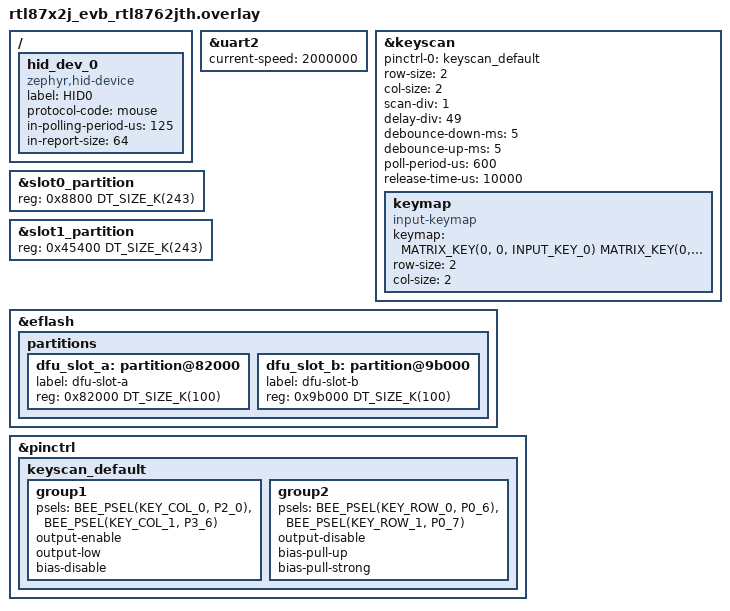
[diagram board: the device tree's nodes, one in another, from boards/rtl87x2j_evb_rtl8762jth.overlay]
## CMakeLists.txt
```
# Copyright (c) 2026 Realtek Semiconductor Corp.
# SPDX-License-Identifier: Apache-2.0

cmake_minimum_required(VERSION 3.20.0)
find_package(Zephyr REQUIRED HINTS $ENV{ZEPHYR_BASE})
project(hid_mouse)

include(${ZEPHYR_BASE}/samples/subsys/usb/common/common.cmake)

target_sources(app PRIVATE src/main.c src/dfu_slots.c)
```

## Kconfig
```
# Copyright (c) 2026, Realtek Semiconductor Corporation
# SPDX-License-Identifier: Apache-2.0

# Pull in the common USB sample options (SAMPLE_USBD_* etc.) - this also
# provides CONFIG_SAMPLE_USBD_REMOTE_WAKEUP which arms the device.
source "samples/subsys/usb/common/Kconfig.sample_usbd"

config APP_DFU_MODE_PID
	hex "Product ID of the DFU mode device"
	default 0xffff
	help
	  Product ID used by the DFU mode device, which replaces the run-time
	  HID device after DFU_DETACH. It must differ from CONFIG_SAMPLE_USBD_PID
	  so the host does not reuse the cached HID configuration.

source "Kconfig.zephyr"
```

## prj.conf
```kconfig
# Copyright (c) 2026 Realtek Semiconductor Corp.
# SPDX-License-Identifier: Apache-2.0

CONFIG_LOG=y
CONFIG_USB_DEVICE_STACK_NEXT=y
CONFIG_USBD_HID_SUPPORT=y
# Remote wakeup: the config descriptor carries the remote-wakeup attribute so
# the host knows the device can wake the bus. The host still must explicitly
# arm it (SET_FEATURE(DEVICE_REMOTE_WAKEUP)) before usbd_wakeup_request()
# succeeds, otherwise it returns -EACCES.
CONFIG_SAMPLE_USBD_REMOTE_WAKEUP=y
CONFIG_INPUT=y
# "stream on|off" switches the continuous reporting.
CONFIG_SHELL=y

# DFU: the run-time instance is registered next to the HID interface, the DFU
# mode instance ("dfu_dfu") is blocklisted by the common sample code and only
# registered by switch_to_dfu_mode(). The built-in flash backend is left off,
# src/dfu_slots.c drives the two partitions through flash_area_* instead.
CONFIG_USBD_DFU=y
CONFIG_USBD_DFU_NUMOF_IMAGES=2
CONFIG_FLASH=y
CONFIG_FLASH_MAP=y
CONFIG_FLASH_PAGE_LAYOUT=y

# switch_to_dfu_mode() runs on the system workqueue (cooperative priority) and
# tears USB down there, which starves the deferred log thread.
CONFIG_LOG_MODE_IMMEDIATE=y

# In immediate mode the whole formatting chain runs inline on the calling
# thread, and z_log_msg_runtime_vcreate() alloca()s the packaged message there,
# so a single log call needs ~1K of stack. The DWC2 driver thread logs from its
# per-transfer path (dwc2_prep_rx(), dwc2_set_dedicated_fifo()), which is more
# than the 512 byte default stack can absorb. Drop those to WRN (as the other
# USB samples do) and give the driver thread room for the WRN/ERR calls that
# remain.
CONFIG_UDC_DRIVER_LOG_LEVEL_WRN=y
CONFIG_USBD_LOG_LEVEL_WRN=y
CONFIG_UDC_DWC2_STACK_SIZE=1024

# Continuous reporting keeps 4 reports in flight, plus the one being released
# when the next is queued and an event report.
CONFIG_USBD_HID_IN_BUF_COUNT=6
```

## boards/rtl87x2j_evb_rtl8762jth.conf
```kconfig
# Copyright (c) 2026 Realtek Semiconductor Corp.
# SPDX-License-Identifier: Apache-2.0

CONFIG_BEE_INPUT_KEYSCAN_AUTOSCAN_MODE=y
# In auto scan mode the keyscan driver reports its events from the ISR with
# K_FOREVER. Through the input thread a full queue then pends whatever thread
# the ISR interrupted, and the input thread runs at the lowest priority, so at
# the 8 kHz report rate it falls behind and the queue does fill up. Run the
# callbacks right in the reporting context instead, they only update a few
# variables.
CONFIG_INPUT_MODE_SYNCHRONOUS=y
```

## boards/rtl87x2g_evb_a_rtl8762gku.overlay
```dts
/*
 * Copyright (c) 2026, Realtek Semiconductor Corporation
 *
 * SPDX-License-Identifier: Apache-2.0
 */

/ {
	hid_dev_0: hid_dev_0 {
		compatible = "zephyr,hid-device";
		label = "HID0";
		/* "mouse" makes the device advertise the HID boot interface
		 * (bInterfaceSubClass=1, bInterfaceProtocol=2), so the host may
		 * switch it to Boot Protocol via SET_PROTOCOL (e.g. BIOS/UEFI).
		 */
		protocol-code = "mouse";
		in-polling-period-us = <1000>;
		in-report-size = <64>;
	};
};

/* The board layout has no slot-0/slot-1 partitions, so the two DFU slots are
 * carved out of the free space that app-image otherwise claims. The 828K
 * between 0x2d000 and 0xfc000 (where storage starts) is split into 316K for
 * the application plus two 256K slots. Both offsets are 4K aligned, matching
 * the flash erase-block size.
 */
&app_partition {
	reg = <0x2d000 DT_SIZE_K(316)>;
};

&flash {
	partitions {
		dfu_slot_a: partition@7c000 {
			label = "dfu-slot-a";
			reg = <0x7c000 DT_SIZE_K(256)>;
		};

		dfu_slot_b: partition@bc000 {
			label = "dfu-slot-b";
			reg = <0xbc000 DT_SIZE_K(256)>;
		};
	};
};
```

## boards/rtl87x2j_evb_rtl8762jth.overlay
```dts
/*
 * Copyright (c) 2026, Realtek Semiconductor Corporation
 *
 * SPDX-License-Identifier: Apache-2.0
 */

#include <zephyr/dt-bindings/input/keymap.h>

/ {
	hid_dev_0: hid_dev_0 {
		compatible = "zephyr,hid-device";
		label = "HID0";
		/* "mouse" makes the device advertise the HID boot interface
		 * (bInterfaceSubClass=1, bInterfaceProtocol=2), so the host may
		 * switch it to Boot Protocol via SET_PROTOCOL (e.g. BIOS/UEFI).
		 */
		protocol-code = "mouse";
		in-polling-period-us = <125>;
		in-report-size = <64>;
	};
};

/* Faster console, so logging keeps up with the 8 kHz report rate. */
&uart2 {
	current-speed = <2000000>;
};

/* Mouse mode: keys are scanned every 1 ms, which is plenty for buttons next to
 * the 8 kHz sensor data. Timing rules:
 *  - The delay clock is 5 MHz / 2 / 50 = 50 kHz (20 us per tick), every timer
 *    counts at most 511 ticks.
 *  - The software debounce only remembers the last 30 scans (30 ms here).
 *  - As a precaution the release time is kept longer than the release
 *    debounce, so the all-release interrupt cannot come before the release
 *    has been debounced.
 */
&keyscan {
	pinctrl-0 = <&keyscan_default>;
	pinctrl-names = "default";
	row-size = <2>;
	col-size = <2>;
	scan-div = <1>;
	delay-div = <49>;
	debounce-down-ms = <5>;
	debounce-up-ms = <5>;
	poll-period-us = <600>;
	release-time-us = <10000>;
	status = "okay";

	/* Turns the row/column events of the matrix into the key codes the
	 * sample handles: left button, right button, move X, move Y.
	 */
	keymap {
		compatible = "input-keymap";
		keymap = <MATRIX_KEY(0, 0, INPUT_KEY_0)
			  MATRIX_KEY(0, 1, INPUT_KEY_1)
			  MATRIX_KEY(1, 0, INPUT_KEY_2)
			  MATRIX_KEY(1, 1, INPUT_KEY_3)>;
		row-size = <2>;
		col-size = <2>;
	};
};

/* The MCUboot layout (boot-patch + two 343K image slots) fills the whole
 * eflash, so both image slots are shrunk to 243K and the two DFU slots take
 * the 200K freed at the end. Both offsets are 1K aligned, matching the eflash
 * erase-block size. MCUboot must see the same layout, see
 * sysbuild/mcuboot.overlay.
 */
&slot0_partition {
	reg = <0x8800 DT_SIZE_K(243)>;
};

&slot1_partition {
	reg = <0x45400 DT_SIZE_K(243)>;
};

&eflash {
	partitions {
		dfu_slot_a: partition@82000 {
			label = "dfu-slot-a";
			reg = <0x82000 DT_SIZE_K(100)>;
		};

		dfu_slot_b: partition@9b000 {
			label = "dfu-slot-b";
			reg = <0x9b000 DT_SIZE_K(100)>;
		};
	};
};

&pinctrl {
	keyscan_default: keyscan_default {
		group1 {
			psels = <BEE_PSEL(KEY_COL_0, P2_0)>,
				<BEE_PSEL(KEY_COL_1, P3_6)>;
			output-enable;
			output-low;
			bias-disable;
		};

		group2 {
			psels = <BEE_PSEL(KEY_ROW_0, P0_6)>,
				<BEE_PSEL(KEY_ROW_1, P0_7)>;
			output-disable;
			bias-pull-up;
			bias-pull-strong;
		};
	};
};
```

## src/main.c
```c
/*
 * Copyright (c) 2026, Realtek Semiconductor Corporation
 *
 * SPDX-License-Identifier: Apache-2.0
 */

/* USB HID mouse demo combining boot-report support and remote wakeup.
 *
 * The device presents a HID mouse that supports the HID *boot interface*
 * (bInterfaceSubClass=1, bInterfaceProtocol=2) *and* is armed for remote
 * wakeup (remote-wakeup attribute in the configuration descriptor).
 *
 * Boot/report protocol switch:
 *   - Report Protocol (HID_PROTOCOL_REPORT, value 1): the 4-byte layout from
 *     the report descriptor.
 *   - Boot Protocol   (HID_PROTOCOL_BOOT, value 0):  the fixed 3-byte boot
 *     mouse report (buttons | X | Y) used by BIOS/UEFI. The host selects the
 *     protocol via SET_PROTOCOL; get_report() answers a host GET_REPORT with
 *     the matching layout.
 *
 * Remote wakeup:
 *   When the host suspends the bus, mouse activity triggers
 *   usbd_wakeup_request(), which drives a bus resume (K state). The suspend
 *   state is polled periodically (PROBE) so a lost USBSUSP interrupt can be
 *   told apart from a host that never suspended the bus.
 *
 * Continuous reporting:
 *   While the mouse is in normal use (configured, Report Protocol, bus not
 *   suspended) a report is sent on every host poll, 8 kHz on rtl87x2j. Under
 *   the Boot Protocol and while the bus is suspended each input event is
 *   handled on its own instead, as a boot report or a remote wakeup request.
 *   The shell command "stream off" stops the stream in Report Protocol too, so
 *   the host sees an idle mouse and may suspend it.
 *
 * DFU:
 *   The DFU run-time instance is registered next to the HID interface, so the
 *   mouse advertises DFU_DETACH. On detach the HID device is torn down and a
 *   separate DFU mode device is brought up, exposing the two flash slots from
 *   src/dfu_slots.c as alternate settings. This is a one way switch, the mouse
 *   only comes back after a reboot.
 */

#include <sample_usbd.h>

#include <string.h>

#include <zephyr/kernel.h>
#include <zephyr/device.h>
#include <zephyr/input/input.h>
#include <zephyr/shell/shell.h>
#include <zephyr/sys/util.h>
#include <zephyr/sys/byteorder.h>
#include <zephyr/sys/atomic.h>
#include <zephyr/drivers/usb/usb_buf.h>

#include <zephyr/usb/usbd.h>
#include <zephyr/usb/class/usbd_hid.h>
#include <zephyr/drivers/usb/udc.h>

#include <zephyr/logging/log.h>
LOG_MODULE_REGISTER(main, LOG_LEVEL_INF);

/*
 * DFU mode device, brought up only after the host requests DFU_DETACH. It uses
 * a different product ID than the run-time device so the host does not reuse
 * the cached HID configuration.
 */
USBD_DEVICE_DEFINE(dfu_usbd,
		   DEVICE_DT_GET(DT_NODELABEL(zephyr_udc0)),
		   CONFIG_SAMPLE_USBD_VID, CONFIG_APP_DFU_MODE_PID);

USBD_DESC_LANG_DEFINE(dfu_lang);
USBD_DESC_CONFIG_DEFINE(dfu_fs_cfg_desc, "DFU FS Configuration");
USBD_DESC_CONFIG_DEFINE(dfu_hs_cfg_desc, "DFU HS Configuration");

static const uint8_t dfu_attributes = (IS_ENABLED(CONFIG_SAMPLE_USBD_SELF_POWERED) ?
				       USB_SCD_SELF_POWERED : 0);

USBD_CONFIGURATION_DEFINE(dfu_fs_config, dfu_attributes,
			  CONFIG_SAMPLE_USBD_MAX_POWER, &dfu_fs_cfg_desc);
USBD_CONFIGURATION_DEFINE(dfu_hs_config, dfu_attributes,
			  CONFIG_SAMPLE_USBD_MAX_POWER, &dfu_hs_cfg_desc);

static void switch_to_dfu_mode(struct usbd_context *const ctx);

/*
 * Custom report descriptor. This is a deliberately non-standard mouse layout
 * to demonstrate that the interrupt report is whatever the descriptor says:
 *
 *   o  buttons : 2 bits (left/right) + 6 bits padding
 *   o  X       : 16-bit signed relative delta
 *   o  Y       : 16-bit signed relative delta
 *   o  wheel   : 8-bit signed
 *
 * Total interrupt report size: 1 + 2 + 2 + 1 = 6 bytes.
 */
static const uint8_t hid_report_desc[] = {
	HID_USAGE_PAGE(HID_USAGE_GEN_DESKTOP),
	HID_USAGE(HID_USAGE_GEN_DESKTOP_MOUSE),
	HID_COLLECTION(HID_COLLECTION_APPLICATION),
		/* 2 button bits */
		HID_USAGE_PAGE(HID_USAGE_GEN_BUTTON),
		HID_USAGE_MIN8(1),
		HID_USAGE_MAX8(2),
		HID_LOGICAL_MIN8(0),
		HID_LOGICAL_MAX8(1),
		HID_REPORT_SIZE(1),
		HID_REPORT_COUNT(2),
		HID_INPUT(0x02),
		/* 6 pad bits to align to a byte */
		HID_REPORT_SIZE(6),
		HID_REPORT_COUNT(1),
		HID_INPUT(0x03),
		/* X: 16-bit signed relative (LE) */
		HID_USAGE_PAGE(HID_USAGE_GEN_DESKTOP),
		HID_USAGE(HID_USAGE_GEN_DESKTOP_X),
		HID_LOGICAL_MIN16(0x00, 0x80),
		HID_LOGICAL_MAX16(0xFF, 0x7F),
		HID_REPORT_SIZE(16),
		HID_REPORT_COUNT(1),
		HID_INPUT(0x06),
		/* Y: 16-bit signed relative (LE) */
		HID_USAGE(HID_USAGE_GEN_DESKTOP_Y),
		HID_LOGICAL_MIN16(0x00, 0x80),
		HID_LOGICAL_MAX16(0xFF, 0x7F),
		HID_REPORT_SIZE(16),
		HID_REPORT_COUNT(1),
		HID_INPUT(0x06),
		/* wheel: 8-bit signed relative */
		HID_USAGE(HID_USAGE_GEN_DESKTOP_WHEEL),
		HID_LOGICAL_MIN8(-127),
		HID_LOGICAL_MAX8(127),
		HID_REPORT_SIZE(8),
		HID_REPORT_COUNT(1),
		HID_INPUT(0x06),
	HID_END_COLLECTION,
};

#define MOUSE_BTN_LEFT	0
#define MOUSE_BTN_RIGHT	1

enum mouse_report_idx {
	MOUSE_BTN_REPORT_IDX = 0,	/* byte 0 : 2 button bits + 6 pad bits */
	MOUSE_X_REPORT_IDX = 1,		/* bytes 1-2 : 16-bit X (LE) */
	MOUSE_Y_REPORT_IDX = 3,		/* bytes 3-4 : 16-bit Y (LE) */
	MOUSE_WHEEL_REPORT_IDX = 5,	/* byte 5 : 8-bit wheel */
	MOUSE_REPORT_COUNT = 6,
};

/* Boot mouse report is fixed at 3 bytes by the HID spec. */
#define BOOT_MOUSE_REPORT_SIZE	3

/*
 * Continuous reporting.
 *
 * While the mouse is in normal use the interrupt IN endpoint is kept
 * permanently fed. Two things make that possible:
 *
 *  - Every report needs its own static buffer, because the buffer passed to
 *    hid_device_submit_report() must stay valid until the transfer completes.
 *  - The next report is queued from input_report_done(), not from the main
 *    loop. The DWC2 IN endpoint can only hold one transfer at a time, so the
 *    driver must find a queued buffer as soon as one completes; waking the
 *    main loop first costs more than the 125 us a high-speed microframe lasts
 *    and the endpoint would answer every other host poll with a NAK.
 */
#define STREAM_SLOTS		4

UDC_STATIC_BUF_DEFINE(stream_buf_0, MOUSE_REPORT_COUNT);
UDC_STATIC_BUF_DEFINE(stream_buf_1, MOUSE_REPORT_COUNT);
UDC_STATIC_BUF_DEFINE(stream_buf_2, MOUSE_REPORT_COUNT);
UDC_STATIC_BUF_DEFINE(stream_buf_3, MOUSE_REPORT_COUNT);

static uint8_t *const stream_bufs[] = {
	stream_buf_0, stream_buf_1, stream_buf_2, stream_buf_3,
};

static atomic_t stream_slot_busy;
static atomic_t stream_sent;
static atomic_t stream_done;
static atomic_t stream_refill_done_ctx;
static atomic_t stream_refill_main_ctx;
static atomic_t stream_key_events;

/* Mouse state from input_cb(), picked up by the next streamed report. */
static atomic_t stream_buttons;
static atomic_t stream_delta_x;
static atomic_t stream_delta_y;

/* Switched by the "stream" shell command. */
static volatile bool stream_enabled = true;

/* Reports for single input events are sent one at a time, outside the
 * stream.
 */
UDC_STATIC_BUF_DEFINE(event_report, MOUSE_REPORT_COUNT);
K_SEM_DEFINE(event_report_free, 1, 1);

K_MSGQ_DEFINE(mouse_msgq, MOUSE_REPORT_COUNT, 4, 1);
static volatile bool mouse_ready;

/* Current HID protocol: HID_PROTOCOL_REPORT (1) or HID_PROTOCOL_BOOT (0). */
static uint8_t protocol = HID_PROTOCOL_REPORT;

/* Last generated report, kept so a GET_REPORT from the host can return the
 * current mouse state. Byte layout matches enum mouse_report_idx.
 */
static uint8_t cur_report[MOUSE_REPORT_COUNT];

/* USB context used by the suspend-state probe and the wake-up path. */
static struct usbd_context *g_usbd;

/* The stream only runs while the mouse is in normal use. */
static bool stream_active(void)
{
	return stream_enabled && mouse_ready &&
	       protocol == HID_PROTOCOL_REPORT && !usbd_is_suspended(g_usbd);
}

static void input_cb(struct input_event *evt, void *user_data)
{
	static uint8_t tmp[MOUSE_REPORT_COUNT];
	static int16_t delta_x;
	static int16_t delta_y;

	ARG_UNUSED(user_data);

#if DT_NODE_HAS_STATUS_OKAY(DT_NODELABEL(keyscan))
	/* Raw row/column events of the key matrix. The input-keymap child node
	 * turns them into the INPUT_KEY_* codes handled below.
	 */
	if (evt->dev == DEVICE_DT_GET(DT_NODELABEL(keyscan))) {
		return;
	}
#endif

	switch (evt->code) {
	case INPUT_KEY_0:
		WRITE_BIT(tmp[MOUSE_BTN_REPORT_IDX], MOUSE_BTN_LEFT, evt->value);
		break;
	case INPUT_KEY_1:
		WRITE_BIT(tmp[MOUSE_BTN_REPORT_IDX], MOUSE_BTN_RIGHT, evt->value);
		break;
	case INPUT_KEY_2:
		if (evt->value) {
			delta_x += 10;
		}

		break;
	case INPUT_KEY_3:
		if (evt->value) {
			delta_y += 10;
		}

		break;
	default:
		LOG_INF("Unrecognized input code %u value %d",
			evt->code, evt->value);
		return;
	}

	/* Encode the 16-bit deltas little-endian. */
	sys_put_le16((uint16_t)delta_x, &tmp[MOUSE_X_REPORT_IDX]);
	sys_put_le16((uint16_t)delta_y, &tmp[MOUSE_Y_REPORT_IDX]);

	atomic_set(&stream_buttons, tmp[MOUSE_BTN_REPORT_IDX]);
	atomic_inc(&stream_key_events);

	if (stream_active()) {
		/* A report goes out on every host poll anyway, the next one
		 * picks up this state.
		 */
		atomic_add(&stream_delta_x, delta_x);
		atomic_add(&stream_delta_y, delta_y);
	} else if (k_msgq_put(&mouse_msgq, tmp, K_NO_WAIT) != 0) {
		LOG_ERR("Failed to put new input event");
	}

	/* Keep the current state for GET_REPORT. Buttons persist; X/Y are
	 * deltas that reset to zero after each event.
	 */
	memcpy(cur_report, tmp, sizeof(cur_report));
	sys_put_le16(0U, &cur_report[MOUSE_X_REPORT_IDX]);
	sys_put_le16(0U, &cur_report[MOUSE_Y_REPORT_IDX]);

	delta_x = 0;
	delta_y = 0;
}

INPUT_CALLBACK_DEFINE(NULL, input_cb, NULL);

static void mouse_iface_ready(const struct device *dev, const bool ready)
{
	LOG_INF("HID device %s interface is %s",
		dev->name, ready ? "ready" : "not ready");

	if (!ready) {
		/* Transfers in flight are gone, later completions are ignored. */
		atomic_clear(&stream_slot_busy);
		k_sem_give(&event_report_free);
	}

	/* The class starts every configuration in Report Protocol without
	 * calling set_protocol(), so a Boot Protocol left over from a BIOS
	 * would otherwise keep the stream off after re-enumeration.
	 */
	protocol = HID_PROTOCOL_REPORT;
	mouse_ready = ready;
}

static int mouse_get_report(const struct device *dev,
			    const uint8_t type, const uint8_t id,
			    const uint16_t len, uint8_t *const buf)
{
	ARG_UNUSED(dev);
	ARG_UNUSED(id);

	if (type != HID_REPORT_TYPE_INPUT) {
		LOG_WRN("Get Report: unsupported type %u", type);
		return -ENOTSUP;
	}

	/* Under the boot protocol the report must use the fixed 3-byte layout
	 * from the HID spec (X/Y are 8-bit there); otherwise the 6-byte custom
	 * layout described by the report descriptor (X/Y 16-bit).
	 */
	if (protocol == HID_PROTOCOL_BOOT) {
		uint8_t boot[BOOT_MOUSE_REPORT_SIZE];

		boot[0] = cur_report[MOUSE_BTN_REPORT_IDX];
		boot[1] = cur_report[MOUSE_X_REPORT_IDX];	/* X low byte */
		boot[2] = cur_report[MOUSE_Y_REPORT_IDX];	/* Y low byte */

		if (len < sizeof(boot)) {
			return -ENOMEM;
		}
		memcpy(buf, boot, sizeof(boot));

		LOG_INF("Get Report (Input, boot): %02x %02x %02x",
			boot[0], boot[1], boot[2]);
		return sizeof(boot);
	}

	if (len < MOUSE_REPORT_COUNT) {
		return -ENOMEM;
	}
	memcpy(buf, cur_report, MOUSE_REPORT_COUNT);

	LOG_INF("Get Report (Input, report, %u bytes): "
		"%02x %02x %02x %02x %02x %02x",
		MOUSE_REPORT_COUNT, cur_report[0], cur_report[1],
		cur_report[2], cur_report[3], cur_report[4], cur_report[5]);
	return MOUSE_REPORT_COUNT;
}

/* Called by the usbd_hid class when the host switches between Boot Protocol
 * and Report Protocol via SET_PROTOCOL.
 */
static void mouse_set_protocol(const struct device *dev, const uint8_t proto)
{
	ARG_UNUSED(dev);

	protocol = proto;
	LOG_INF("HID protocol set to %s",
		proto == HID_PROTOCOL_BOOT ? "Boot" : "Report");
}

/*
 * Build a report whose X delta alternates +1/-1, so the host keeps receiving
 * data (the cursor only jitters by one pixel) and no report is dropped by the
 * HID stack as "no change". Buttons and the movement from input_cb() are
 * added on top.
 */
static bool stream_submit(int slot, const struct device *hid_dev)
{
	uint8_t *report = stream_bufs[slot];
	int16_t jitter = (atomic_get(&stream_sent) & 1) ? 1 : -1;
	int ret;

	memset(report, 0, MOUSE_REPORT_COUNT);
	report[MOUSE_BTN_REPORT_IDX] = atomic_get(&stream_buttons);
	sys_put_le16((uint16_t)(jitter + atomic_clear(&stream_delta_x)),
		     &report[MOUSE_X_REPORT_IDX]);
	sys_put_le16((uint16_t)atomic_clear(&stream_delta_y),
		     &report[MOUSE_Y_REPORT_IDX]);

	ret = hid_device_submit_report(hid_dev, MOUSE_REPORT_COUNT, report);
	if (ret != 0) {
		atomic_clear_bit(&stream_slot_busy, slot);
		return false;
	}

	atomic_inc(&stream_sent);
	return true;
}

/* Submit every free slot. */
static void stream_fill(const struct device *hid_dev)
{
	for (int i = 0; i < STREAM_SLOTS; i++) {
		if (!atomic_test_and_set_bit(&stream_slot_busy, i) &&
		    stream_submit(i, hid_dev)) {
			atomic_inc(&stream_refill_main_ctx);
		}
	}
}

/*
 * Print the achieved report rate every 5 s while the stream runs. Divide by
 * the real elapsed time, not by an assumed interval: the main thread is
 * preemptible and the cooperative USB threads can starve it for a long time
 * at this rate. While the stream is stopped the counters are only reset, so
 * the first line after a restart covers the stream alone.
 */
static void stream_stats(bool active)
{
	static uint32_t sent_prev;
	static uint32_t done_prev;
	static int64_t t_prev;
	uint32_t sent = (uint32_t)atomic_get(&stream_sent);
	uint32_t done = (uint32_t)atomic_get(&stream_done);
	int64_t now = k_uptime_get();

	if (active) {
		uint32_t elapsed = (uint32_t)(now - t_prev);

		if (elapsed < 5000U) {
			return;
		}

		LOG_INF("sent/s %u done/s %u | refill done_ctx %u main_ctx %u"
			" | key events %u",
			(sent - sent_prev) * 1000U / elapsed,
			(done - done_prev) * 1000U / elapsed,
			(uint32_t)atomic_get(&stream_refill_done_ctx),
			(uint32_t)atomic_get(&stream_refill_main_ctx),
			(uint32_t)atomic_get(&stream_key_events));
	}

	atomic_clear(&stream_refill_done_ctx);
	atomic_clear(&stream_refill_main_ctx);
	atomic_clear(&stream_key_events);
	sent_prev = sent;
	done_prev = done;
	t_prev = now;
}

static void mouse_input_done(const struct device *dev,
			     const uint8_t *const report)
{
	if (report == event_report) {
		k_sem_give(&event_report_free);
		return;
	}

	for (int i = 0; i < STREAM_SLOTS; i++) {
		if (report != stream_bufs[i]) {
			continue;
		}

		if (!atomic_test_and_clear_bit(&stream_slot_busy, i)) {
			return;
		}

		atomic_inc(&stream_done);

		/* Queue the next report right here: the driver arms the next
		 * buffer as soon as this completion returns. Once the stream
		 * stops, the slot stays free until the main loop restarts it.
		 */
		if (stream_active() &&
		    !atomic_test_and_set_bit(&stream_slot_busy, i) &&
		    stream_submit(i, dev)) {
			atomic_inc(&stream_refill_done_ctx);
		}

		return;
	}
}

static int cmd_stream_status(const struct shell *sh, size_t argc, char **argv)
{
	ARG_UNUSED(argc);
	ARG_UNUSED(argv);

	shell_print(sh, "stream %s, %s", stream_enabled ? "on" : "off",
		    stream_active() ? "running" : "stopped");
	return 0;
}

static int cmd_stream_on(const struct shell *sh, size_t argc, char **argv)
{
	stream_enabled = true;
	return cmd_stream_status(sh, argc, argv);
}

static int cmd_stream_off(const struct shell *sh, size_t argc, char **argv)
{
	stream_enabled = false;
	return cmd_stream_status(sh, argc, argv);
}

SHELL_STATIC_SUBCMD_SET_CREATE(stream_cmds,
	SHELL_CMD(on, NULL, "Start continuous reporting", cmd_stream_on),
	SHELL_CMD(off, NULL, "Report on input events only", cmd_stream_off),
	SHELL_SUBCMD_SET_END
);

SHELL_CMD_REGISTER(stream, &stream_cmds, "Continuous reporting control",
		   cmd_stream_status);

struct hid_device_ops mouse_ops = {
	.iface_ready = mouse_iface_ready,
	.get_report = mouse_get_report,
	.set_protocol = mouse_set_protocol,
	.input_report_done = mouse_input_done,
};

/* Periodically print the bus suspend state. This polls the stack flags rather
 * than relying on suspend/resume events, so that a missing UDC interrupt can
 * be told apart from a host that never suspended the bus.
 */
static void bus_state_probe(struct k_work *work)
{
	struct k_work_delayable *dwork = k_work_delayable_from_work(work);
	static bool last_suspended;
	bool suspended;

	if (g_usbd == NULL) {
		goto reschedule;
	}

	suspended = usbd_is_suspended(g_usbd);

	if (suspended != last_suspended) {
		LOG_INF("PROBE: bus state changed -> %s [usbd=%d udc=%d rwup=%d]",
			suspended ? "SUSPENDED" : "ACTIVE",
			suspended, udc_is_suspended(g_usbd->dev),
			g_usbd->status.rwup);
		last_suspended = suspended;
	} else {
		LOG_DBG("PROBE: %s [usbd=%d udc=%d rwup=%d]",
			suspended ? "SUSPENDED" : "ACTIVE",
			suspended, udc_is_suspended(g_usbd->dev),
			g_usbd->status.rwup);
	}

reschedule:
	(void)k_work_reschedule(dwork, K_SECONDS(1));
}

static K_WORK_DELAYABLE_DEFINE(probe_work, bus_state_probe);

static void msg_cb(struct usbd_context *const usbd_ctx,
		   const struct usbd_msg *const msg)
{
	LOG_INF("USBD message: %s [usbd=%d udc=%d]",
		usbd_msg_type_string(msg->type),
		usbd_is_suspended(usbd_ctx), udc_is_suspended(usbd_ctx->dev));

	if (usbd_can_detect_vbus(usbd_ctx)) {
		if (msg->type == USBD_MSG_VBUS_READY) {
			if (usbd_enable(usbd_ctx)) {
				LOG_ERR("Failed to enable device support");
			}
		}

		if (msg->type == USBD_MSG_VBUS_REMOVED) {
			if (usbd_disable(usbd_ctx)) {
				LOG_ERR("Failed to disable device support");
			}
		}
	}

	if (msg->type == USBD_MSG_DFU_APP_DETACH) {
		switch_to_dfu_mode(usbd_ctx);
	}
}

/* Tear down the run-time (HID) device and bring up the DFU mode device in its
 * place. Runs on the system workqueue from the DFU class detach handler.
 */
static void switch_to_dfu_mode(struct usbd_context *const ctx)
{
	int err;

	LOG_INF("Detach USB device, switching to DFU mode");
	usbd_disable(ctx);
	usbd_shutdown(ctx);

	err = usbd_add_descriptor(&dfu_usbd, &dfu_lang);
	if (err) {
		LOG_ERR("Failed to add language descriptor (%d)", err);
		return;
	}

	if (USBD_SUPPORTS_HIGH_SPEED &&
	    usbd_caps_speed(&dfu_usbd) == USBD_SPEED_HS) {
		err = usbd_add_configuration(&dfu_usbd, USBD_SPEED_HS, &dfu_hs_config);
		if (err) {
			LOG_ERR("Failed to add High-Speed configuration");
			return;
		}

		err = usbd_register_class(&dfu_usbd, "dfu_dfu", USBD_SPEED_HS, 1);
		if (err) {
			LOG_ERR("Failed to register DFU mode class (HS)");
			return;
		}

		usbd_device_set_code_triple(&dfu_usbd, USBD_SPEED_HS, 0, 0, 0);
	}

	err = usbd_add_configuration(&dfu_usbd, USBD_SPEED_FS, &dfu_fs_config);
	if (err) {
		LOG_ERR("Failed to add Full-Speed configuration");
		return;
	}

	err = usbd_register_class(&dfu_usbd, "dfu_dfu", USBD_SPEED_FS, 1);
	if (err) {
		LOG_ERR("Failed to register DFU mode class (FS)");
		return;
	}

	usbd_device_set_code_triple(&dfu_usbd, USBD_SPEED_FS, 0, 0, 0);

	err = usbd_init(&dfu_usbd);
	if (err) {
		LOG_ERR("Failed to initialize DFU mode device (%d)", err);
		return;
	}

	err = usbd_msg_register_cb(&dfu_usbd, msg_cb);
	if (err) {
		LOG_ERR("Failed to register message callback (%d)", err);
		return;
	}

	g_usbd = &dfu_usbd;

	err = usbd_enable(&dfu_usbd);
	if (err) {
		LOG_ERR("Failed to enable DFU mode device (%d)", err);
	}
}

int main(void)
{
	struct usbd_context *sample_usbd;
	const struct device *hid_dev;
	int ret;

	hid_dev = DEVICE_DT_GET_ONE(zephyr_hid_device);
	if (!device_is_ready(hid_dev)) {
		LOG_ERR("HID Device is not ready");
		return -EIO;
	}

	ret = hid_device_register(hid_dev, hid_report_desc,
				  sizeof(hid_report_desc), &mouse_ops);
	if (ret != 0) {
		LOG_ERR("Failed to register HID Device, %d", ret);
		return ret;
	}

	sample_usbd = sample_usbd_init_device(msg_cb);
	if (sample_usbd == NULL) {
		LOG_ERR("Failed to initialize USB device");
		return -ENODEV;
	}

	g_usbd = sample_usbd;

	if (!usbd_can_detect_vbus(sample_usbd)) {
		ret = usbd_enable(sample_usbd);
		if (ret != 0) {
			LOG_ERR("Failed to enable device support");
			return ret;
		}
	}

	LOG_INF("HID mouse sample started (protocol=%s, rwup_armed=%d)",
		protocol == HID_PROTOCOL_BOOT ? "Boot" : "Report",
		sample_usbd->status.rwup);

	(void)k_work_reschedule(&probe_work, K_SECONDS(1));

	while (true) {
		uint8_t report[MOUSE_REPORT_COUNT];
		bool active = stream_active();

		/* (Re)start the stream once the mouse is in normal use: after
		 * enumeration, after a resume, or after SET_PROTOCOL back to
		 * Report. While it runs, every slot is busy and this does
		 * nothing.
		 */
		if (active) {
			stream_fill(hid_dev);
		}

		stream_stats(active);

		if (k_msgq_get(&mouse_msgq, report, K_MSEC(10)) != 0) {
			continue;
		}

		if (!mouse_ready) {
			LOG_INF("USB HID device is not ready");
			continue;
		}

		if (usbd_is_suspended(sample_usbd)) {
			/* Bus suspended: wake it with K state instead of
			 * sending the report blindly.
			 */
			ret = usbd_wakeup_request(sample_usbd);
			if (ret) {
				LOG_ERR("Remote wakeup error, %d", ret);
			} else {
				LOG_INF("Remote wakeup requested");
			}
			continue;
		}

		if (stream_enabled && protocol == HID_PROTOCOL_REPORT) {
			/* Queued before the stream started, hand the movement
			 * over to it.
			 */
			atomic_add(&stream_delta_x,
				   (int16_t)sys_get_le16(&report[MOUSE_X_REPORT_IDX]));
			atomic_add(&stream_delta_y,
				   (int16_t)sys_get_le16(&report[MOUSE_Y_REPORT_IDX]));
			continue;
		}

		if (k_sem_take(&event_report_free, K_MSEC(100)) != 0) {
			LOG_WRN("Event report still in flight, event dropped");
			continue;
		}

		/* Under the boot protocol the report must use the fixed 3-byte
		 * layout from the HID spec instead of the 6-byte custom
		 * Report-Protocol layout defined by the report descriptor.
		 */
		if (protocol == HID_PROTOCOL_BOOT) {
			event_report[0] = report[MOUSE_BTN_REPORT_IDX];
			event_report[1] = report[MOUSE_X_REPORT_IDX];
			event_report[2] = report[MOUSE_Y_REPORT_IDX];

			ret = hid_device_submit_report(hid_dev,
					BOOT_MOUSE_REPORT_SIZE, event_report);
		} else {
			memcpy(event_report, report, MOUSE_REPORT_COUNT);

			ret = hid_device_submit_report(hid_dev,
					MOUSE_REPORT_COUNT, event_report);
		}

		if (ret) {
			k_sem_give(&event_report_free);
			LOG_ERR("HID submit report error, %d", ret);
		}
	}

	return 0;
}
```

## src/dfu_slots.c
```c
/*
 * Copyright (c) 2026, Realtek Semiconductor Corporation
 *
 * SPDX-License-Identifier: Apache-2.0
 */

/* Two-slot USB DFU backend built directly on the flash map.
 *
 * The in-tree backend (CONFIG_USBD_DFU_FLASH) writes through flash_img_*,
 * which resolves to a single compile-time area ID, so the alternate setting
 * selected by the host is ignored on download. This backend uses flash_area_*
 * per image instead, so each alternate setting gets its own base and size
 * straight from its partition:
 *
 *   alt 0 -> dfu_slot_a
 *   alt 1 -> dfu_slot_b
 *
 * The alternate setting number is the position of the image in the linker
 * section, which is sorted by the first USBD_DFU_DEFINE_IMG() argument, hence
 * the "a"/"b" suffixes.
 */

#include <zephyr/drivers/flash.h>
#include <zephyr/storage/flash_map.h>
#include <zephyr/sys/util.h>
#include <zephyr/usb/usbd.h>
#include <zephyr/usb/class/usbd_dfu.h>

#include <zephyr/logging/log.h>
LOG_MODULE_REGISTER(dfu_slots, LOG_LEVEL_INF);

struct dfu_slot_data {
	const uint8_t area_id;
	uint32_t last_block;
	/* Bytes read or written so far, relative to the partition start. */
	uint32_t offset;
	/* Bytes erased so far, relative to the partition start. */
	uint32_t erased;
};

static struct dfu_slot_data slot_a_data = {
	.area_id = PARTITION_ID(dfu_slot_a),
};

static struct dfu_slot_data slot_b_data = {
	.area_id = PARTITION_ID(dfu_slot_b),
};

/* Erase pages lazily, up to the byte the current download needs. */
static int slot_erase_upto(const struct flash_area *const fa,
			   struct dfu_slot_data *const data, const uint32_t needed)
{
	while (data->erased < needed) {
		struct flash_pages_info info;
		int ret;

		ret = flash_get_page_info_by_offs(fa->fa_dev, fa->fa_off + data->erased,
						  &info);
		if (ret) {
			return ret;
		}

		ret = flash_area_erase(fa, data->erased, info.size);
		if (ret) {
			return ret;
		}

		data->erased += info.size;
	}

	return 0;
}

static int slot_read(void *const priv, const uint32_t block, const uint16_t size,
		     uint8_t buf[static CONFIG_USBD_DFU_TRANSFER_SIZE])
{
	struct dfu_slot_data *const data = priv;
	const struct flash_area *fa;
	uint32_t len;
	int ret;

	if (size == 0) {
		/* There is nothing to upload */
		return 0;
	}

	if (block == 0) {
		data->last_block = 0;
		data->offset = 0;
	} else if (data->last_block + 1U != block) {
		return -EINVAL;
	}

	ret = flash_area_open(data->area_id, &fa);
	if (ret) {
		return ret;
	}

	len = MIN(size, fa->fa_size - data->offset);
	if (len == 0) {
		/* Partition fully uploaded, a short packet ends the transfer */
		flash_area_close(fa);
		return 0;
	}

	ret = flash_area_read(fa, data->offset, buf, len);
	flash_area_close(fa);
	if (ret) {
		LOG_ERR("Failed to read area %u at 0x%x (%d)", data->area_id,
			data->offset, ret);
		return ret;
	}

	data->last_block = block;
	data->offset += len;
	LOG_DBG("area %u block %u uploaded %u", data->area_id, block, data->offset);

	return len;
}

static int slot_write(void *const priv, const uint32_t block, const uint16_t size,
		      const uint8_t buf[static CONFIG_USBD_DFU_TRANSFER_SIZE])
{
	struct dfu_slot_data *const data = priv;
	const struct flash_area *fa;
	int ret;

	if (block == 0) {
		data->last_block = 0;
		data->offset = 0;
		data->erased = 0;
	} else if (data->last_block + 1U != block) {
		return -EINVAL;
	}

	if (size == 0) {
		/* Zero length download ends the transfer, nothing is buffered */
		LOG_INF("area %u download finished, %u bytes", data->area_id,
			data->offset);
		return 0;
	}

	ret = flash_area_open(data->area_id, &fa);
	if (ret) {
		return ret;
	}

	if (data->offset + size > fa->fa_size) {
		LOG_ERR("Image does not fit into area %u (%u bytes)", data->area_id,
			fa->fa_size);
		flash_area_close(fa);
		return -ENOSPC;
	}

	ret = slot_erase_upto(fa, data, data->offset + size);
	if (ret) {
		LOG_ERR("Failed to erase area %u (%d)", data->area_id, ret);
		flash_area_close(fa);
		return ret;
	}

	/* Both Bee flash drivers advertise write-block-size 1, so a short last
	 * block needs no padding.
	 */
	ret = flash_area_write(fa, data->offset, buf, size);
	flash_area_close(fa);
	if (ret) {
		LOG_ERR("Failed to write area %u at 0x%x (%d)", data->area_id,
			data->offset, ret);
		return ret;
	}

	data->last_block = block;
	data->offset += size;
	LOG_DBG("area %u block %u downloaded %u", data->area_id, block, data->offset);

	return 0;
}

USBD_DFU_DEFINE_IMG(dfu_slot_a, "slot-a", &slot_a_data, slot_read, slot_write, NULL);
USBD_DFU_DEFINE_IMG(dfu_slot_b, "slot-b", &slot_b_data, slot_read, slot_write, NULL);
```
